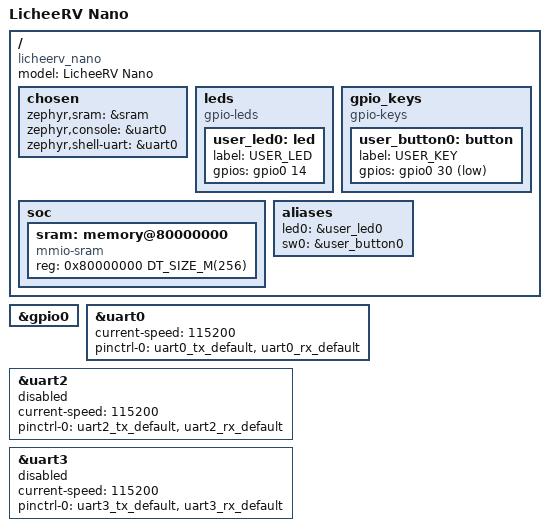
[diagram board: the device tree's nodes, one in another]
/*
 * Copyright (c) 2023 ZHOU Kejun <zhoukejun@outlook.com>
 *
 * SPDX-License-Identifier: Apache-2.0
 */

/dts-v1/;
#include <mem.h>
#include <zephyr/dt-bindings/gpio/gpio.h>
#include <sophgo/sg200x-c906b.dtsi>
#include "licheerv_nano_c906b-pinctrl.dtsi"

/ {

	model = "LicheeRV Nano";
	compatible = "licheerv_nano";
	chosen {
		zephyr,sram = &sram;
		zephyr,console = &uart0;
		zephyr,shell-uart = &uart0;
	};

	leds {
		compatible = "gpio-leds";
		user_led0: led {
			label = "USER_LED";
			gpios = <&gpio0 14 GPIO_ACTIVE_HIGH>;
		};

	};

	gpio_keys {
		compatible = "gpio-keys";

		user_button0: button {
			label = "USER_KEY";
			gpios = <&gpio0 30 GPIO_ACTIVE_LOW>;
		};
	};

	soc {
		#address-cells = <1>;
		#size-cells = <1>;
		sram: memory@80000000 {
			compatible = "mmio-sram";
			reg = <0x80000000 DT_SIZE_M(256)>;
		};
	};

        aliases {
                led0 = &user_led0;
                sw0 = &user_button0;
	};
};

&gpio0 {
	status = "okay";
};

&uart0 {
	current-speed = <115200>;
	pinctrl-0 = <&uart0_tx_default &uart0_rx_default>;
	pinctrl-names = "default";
	status = "okay";
};

&uart2 {
	current-speed = <115200>;
	pinctrl-0 = <&uart2_tx_default &uart2_rx_default>;
	pinctrl-names = "default";
	status = "disabled";
};

&uart3 {
	current-speed = <115200>;
	pinctrl-0 = <&uart3_tx_default &uart3_rx_default>;
	pinctrl-names = "default";
	status = "disabled";
};

